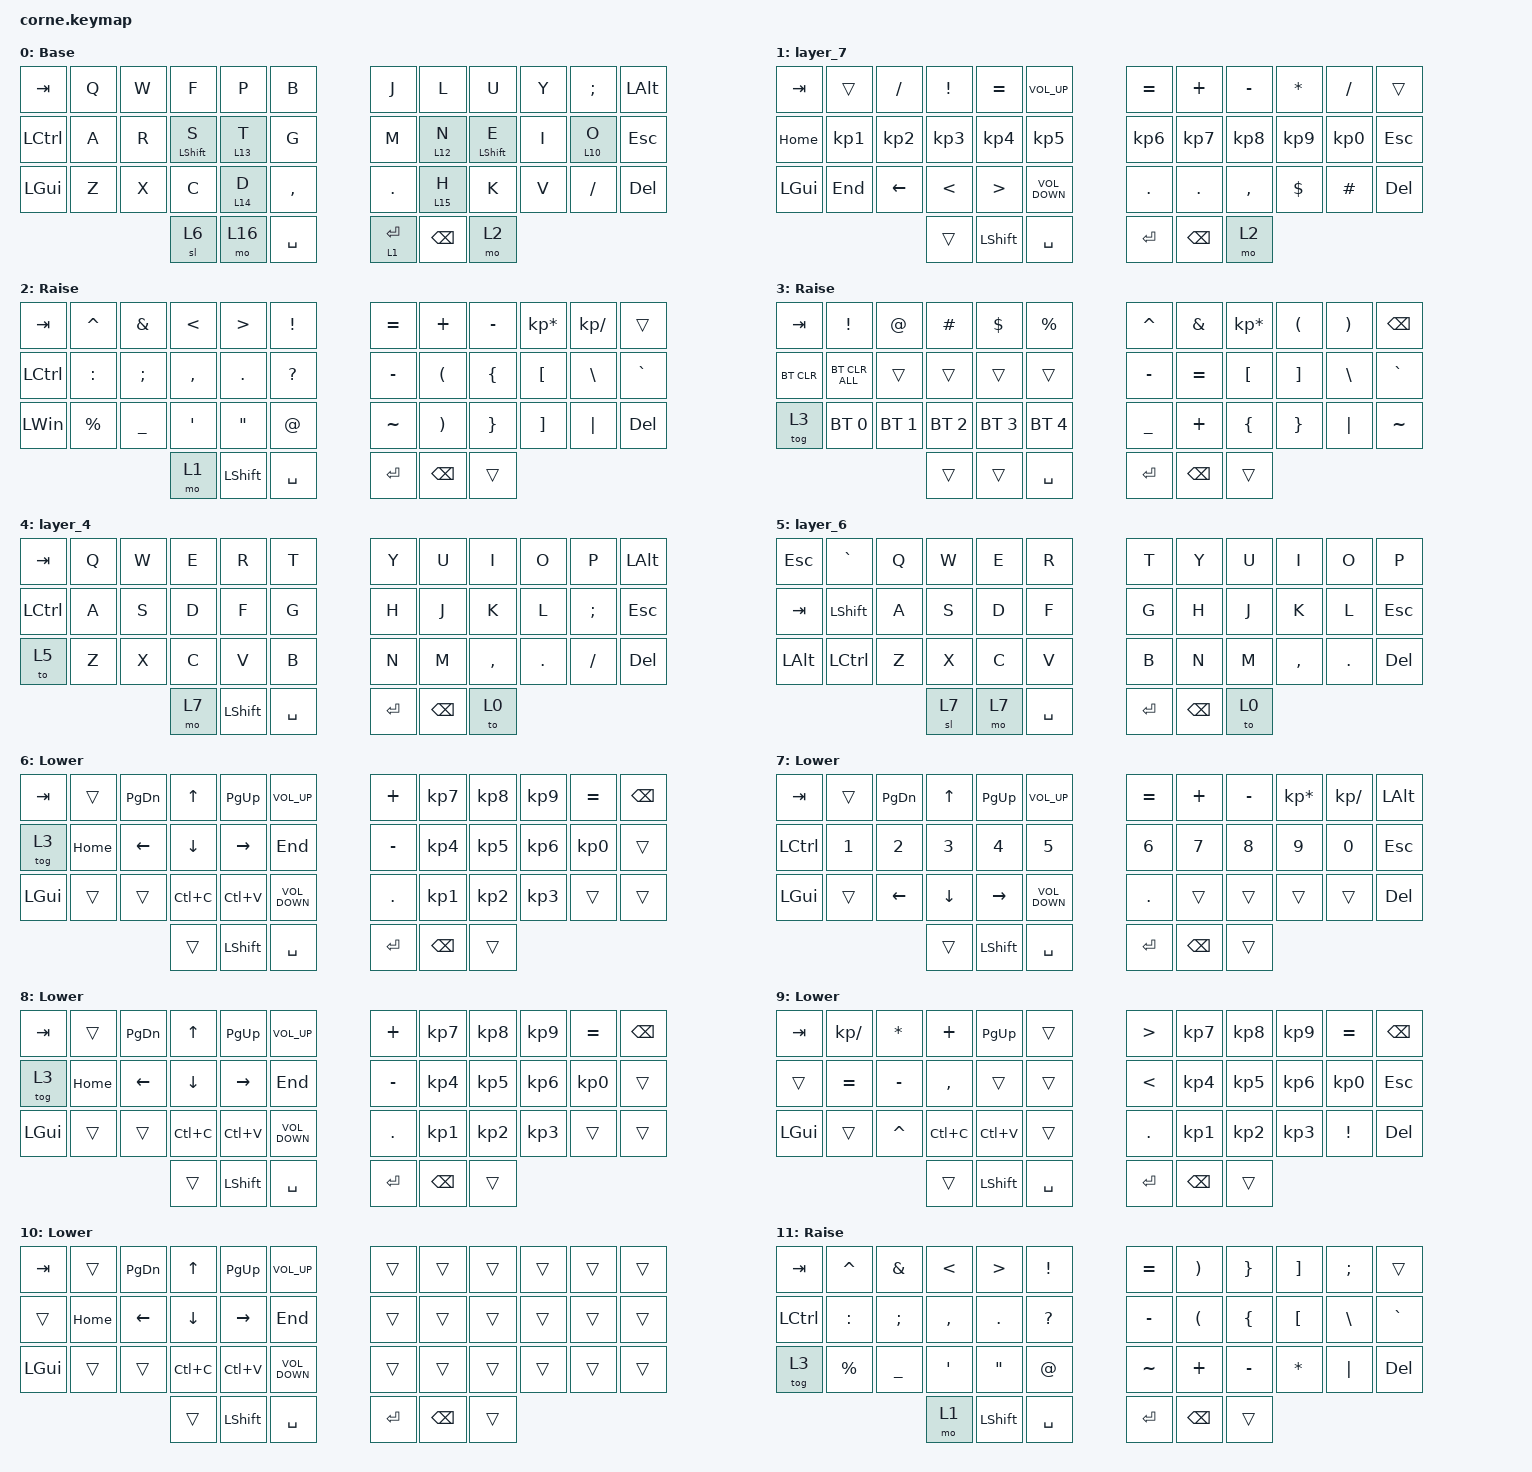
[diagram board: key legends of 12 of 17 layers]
/*
 * Copyright (c) 2020 The ZMK Contributors
 *
 * SPDX-License-Identifier: MIT
 */

#include <behaviors.dtsi>
#include <dt-bindings/zmk/bt.h>
#include <dt-bindings/zmk/keys.h>
#include <dt-bindings/zmk/pointing.h>

/ {
    behaviors {
        HMR: HMR {
            compatible = "zmk,behavior-hold-tap";
            label = "HMR";
            bindings = <&mo>, <&kp>;

            #binding-cells = <2>;
            tapping-term-ms = <200>;
            quick-tap-ms = <175>;
            flavor = "balanced";
            hold-trigger-key-positions = <0 1 2 3 4 5 12 13 14 15 16 17 24 25 26 27 28 29 36 37 38 39 40 41 6 7 8 9 10 11 18 19 20 21 22 23 30 31 32 33 34 35 40 41>;
            hold-trigger-on-release;
        };

        HML: HML {
            compatible = "zmk,behavior-hold-tap";
            label = "HML";
            bindings = <&mo>, <&kp>;

            #binding-cells = <2>;
            tapping-term-ms = <280>;
            quick-tap-ms = <175>;
            flavor = "balanced";
            hold-trigger-on-release;
            hold-trigger-key-positions = <36 37 38 6 7 8 9 10 11 18 19 20 21 22 23 30 31 32 33 34 35 39 40 41>;
            require-prior-idle-ms = <150>;
        };

        HMR2: HMR2 {
            compatible = "zmk,behavior-hold-tap";
            label = "HMR2";
            bindings = <&mo>, <&kp>;

            #binding-cells = <2>;
            tapping-term-ms = <280>;
            quick-tap-ms = <175>;
            flavor = "balanced";
            hold-trigger-on-release;
            hold-trigger-key-positions = <0 1 2 3 4 5 12 13 14 15 16 17 24 25 26 27 28 29 36 37 38 39 40 41>;
            require-prior-idle-ms = <150>;
        };

        HML_Shift: HML_Shift {
            compatible = "zmk,behavior-hold-tap";
            label = "HML_SHIFT";
            bindings = <&kp>, <&kp>;

            #binding-cells = <2>;
            tapping-term-ms = <280>;
            quick-tap-ms = <175>;
            flavor = "balanced";
            hold-trigger-on-release;
            hold-trigger-key-positions = <36 37 38 6 7 8 9 10 11 18 19 20 21 22 23 30 31 32 33 34 35 39 40 41>;
            require-prior-idle-ms = <150>;
        };

        HMR_Shift: HMR_Shift {
            compatible = "zmk,behavior-hold-tap";
            label = "HMR_SHIFT";
            bindings = <&kp>, <&kp>;

            #binding-cells = <2>;
            tapping-term-ms = <280>;
            quick-tap-ms = <175>;
            flavor = "balanced";
            hold-trigger-on-release;
            hold-trigger-key-positions = <0 1 2 3 4 5 12 13 14 15 16 17 24 25 26 27 28 29 36 37 38 39 40 41>;
            require-prior-idle-ms = <150>;
        };
    };

    combos {
        compatible = "zmk,combos";

        wasd {
            bindings = <&to 5>;
            key-positions = <24 12 35 23>;
        };

        home_row_numbers {
            bindings = <&sl 8>;
            key-positions = <36 41>;
        };

        gameObject {
            bindings = <&gameObject>;
            key-positions = <17 22 13>;
        };

        transform {
            bindings = <&transform>;
            key-positions = <16 14 19>;
        };

        this {
            bindings = <&this>;
            key-positions = <16 31 21 15>;
        };

        the {
            bindings = <&the>;
            key-positions = <16 31 20>;
        };

        for {
            bindings = <&for>;
            key-positions = <3 22 14>;
        };

        foreach {
            bindings = <&foreach>;
            key-positions = <3 22 14 20>;
        };

        while {
            bindings = <&while>;
            key-positions = <2 31 21>;
        };

        public {
            bindings = <&public>;
            key-positions = <4 8 7>;
        };

        private {
            bindings = <&private>;
            key-positions = <4 14 21>;
        };

        GameObjectMaj {
            bindings = <&GameObjectMaj>;
            key-positions = <17 22 13 37>;
        };

        TransformMaj {
            bindings = <&TransformMaj>;
            key-positions = <16 14 19 37>;
        };

        BlueTooth {
            bindings = <&tog 3>;
            key-positions = <0 1 13 12>;
        };
    };

    macros {
        gameObject: gameObject {
            compatible = "zmk,behavior-macro";
            #binding-cells = <0>;
            bindings =
                <&macro_tap_time 0>,
                <&kp G &kp A &kp M &kp E &kp LS(O) &kp B &kp J &kp E &kp C &kp T>;

            label = "GAMEOBJECT";
            wait-ms = <0>;
            tap-ms = <0>;
        };

        GameObjectMaj: GameObjectMaj {
            compatible = "zmk,behavior-macro";
            #binding-cells = <0>;
            bindings =
                <&macro_tap_time 0>,
                <&kp LS(G) &kp A &kp M &kp E &kp LS(O) &kp B &kp J &kp E &kp C &kp T>;

            label = "GAMEOBJECTMAJ";
            wait-ms = <0>;
            tap-ms = <0>;
        };

        TransformMaj: TransformMaj {
            compatible = "zmk,behavior-macro";
            #binding-cells = <0>;
            bindings =
                <&macro_tap_time 0>,
                <&kp LS(T) &kp R &kp A &kp N &kp S &kp F &kp O &kp R &kp M>;

            label = "TRANSFORMMAJ";
        };

        public: public {
            compatible = "zmk,behavior-macro";
            #binding-cells = <0>;
            bindings =
                <&macro_tap_time 0>,
                <&kp P &kp U &kp B &kp L &kp I &kp C>;

            label = "PUBLIC";
        };

        private: private {
            compatible = "zmk,behavior-macro";
            #binding-cells = <0>;
            bindings =
                <&macro_tap_time 0>,
                <&kp P &kp R &kp I &kp V &kp A &kp T &kp E>;

            label = "PRIVATE";
        };

        the: the {
            compatible = "zmk,behavior-macro";
            #binding-cells = <0>;
            bindings = <&macro_tap_time 0>, <&kp T &kp H &kp E>;

            label = "THE";
        };

        this: this {
            compatible = "zmk,behavior-macro";
            #binding-cells = <0>;
            bindings = <&macro_tap_time 0>, <&kp T &kp H &kp I &kp S>;

            label = "THIS";
        };

        for: for {
            compatible = "zmk,behavior-macro";
            #binding-cells = <0>;
            bindings = <&macro_tap_time 0>, <&kp F &kp O &kp R>;

            label = "FOR";
        };

        foreach: foreach {
            compatible = "zmk,behavior-macro";
            #binding-cells = <0>;
            bindings =
                <&macro_tap_time 0>,
                <&kp F &kp O &kp R &kp E &kp A &kp C &kp H>;

            label = "FOREACH";
        };

        while: while {
            compatible = "zmk,behavior-macro";
            #binding-cells = <0>;
            bindings = <&macro_tap_time 0>, <&kp W &kp H &kp I &kp L &kp E>;

            label = "WHILE";
        };

        transform: transform {
            compatible = "zmk,behavior-macro";
            #binding-cells = <0>;
            bindings =
                <&macro_tap_time 0>,
                <&kp T &kp R &kp A &kp N &kp S &kp F &kp O &kp R &kp M>;

            label = "TRANSFORM";
            wait-ms = <0>;
            tap-ms = <0>;
        };

        even: even {
            compatible = "zmk,behavior-macro";
            #binding-cells = <0>;
            bindings = <&macro_tap_time 0>, <&kp E &kp V &kp E &kp N &kp SPACE>;

            label = "EVEN";
            wait-ms = <0>;
            tap-ms = <0>;
        };

        made: made {
            compatible = "zmk,behavior-macro";
            #binding-cells = <0>;
            bindings = <&macro_tap_time 0>, <&kp M &kp A &kp D &kp E &kp SPACE>;

            label = "MADE";
            wait-ms = <0>;
            tap-ms = <0>;
        };

        then: then {
            compatible = "zmk,behavior-macro";
            #binding-cells = <0>;
            bindings = <&macro_tap_time 0>, <&kp T &kp H &kp E &kp N &kp SPACE>;

            label = "THEN";
            wait-ms = <0>;
            tap-ms = <0>;
        };

        city: city {
            compatible = "zmk,behavior-macro";
            #binding-cells = <0>;
            bindings = <&macro_tap_time 0>;
            label = "CITY";
            wait-ms = <0>;
            tap-ms = <0>;
        };
    };

    keymap {
        compatible = "zmk,keymap";

        default_layer {
            // -----------------------------------------------------------------------------------------
            // |  TAB |  Q  |  W  |  E  |  R  |  T  |   |  Y  |  U   |  I  |  O  |  P  | BKSP |
            // | CTRL |  A  |  S  |  D  |  F  |  G  |   |  H  |  J   |  K  |  L  |  ;  |  '   |
            // | SHFT |  Z  |  X  |  C  |  V  |  B  |   |  N  |  M   |  ,  |  .  |  /  | ESC  |
            //                    | GUI | LWR | SPC |   | ENT | RSE  | ALT |

            display-name = "Base";
            bindings = <
&kp TAB       &kp Q  &kp W  &kp F                &kp P      &kp B        &kp J          &kp L       &kp U                    &kp Y  &kp SEMICOLON  &kp LEFT_ALT
&kp LCTRL     &kp A  &kp R  &HML_Shift LSHIFT S  &HML 13 T  &kp G        &kp M          &HMR2 12 N  &HMR_Shift LEFT_SHIFT E  &kp I  &HMR2 10 O     &kp ESCAPE
&kp LEFT_GUI  &kp Z  &kp X  &kp C                &HML 14 D  &kp COMMA    &kp DOT        &HMR2 15 H  &kp K                    &kp V  &kp FSLH       &kp DELETE
                            &sl 6                &mo 16     &kp SPACE    &HMR 1 RETURN  &kp BSPC    &mo 2
            >;
        };

        layer_7 {
            bindings = <
&kp TAB   &trans           &kp SLASH  &kp EXCLAMATION  &kp EQUAL         &kp C_VOLUME_UP      &kp EQUAL        &kp PLUS         &kp MINUS        &kp STAR         &kp FSLH         &trans
&kp HOME  &kp KP_NUMBER_1  &kp KP_N2  &kp KP_NUMBER_3  &kp KP_NUMBER_4   &kp KP_NUMBER_5      &kp KP_NUMBER_6  &kp KP_NUMBER_7  &kp KP_NUMBER_8  &kp KP_NUMBER_9  &kp KP_NUMBER_0  &kp ESC
&kp LGUI  &kp END          &kp LEFT   &kp LESS_THAN    &kp GREATER_THAN  &kp C_VOLUME_DOWN    &kp DOT          &kp DOT          &kp COMMA        &kp DOLLAR       &kp HASH         &kp DEL
                                      &trans           &kp LEFT_SHIFT    &kp SPACE            &kp RET          &kp BSPC         &mo 2
            >;
        };

        raise_layer {
            // -----------------------------------------------------------------------------------------
            // |  TAB |  !  |  @  |  #  |  $  |  %  |   |  ^  |  &  |  *  |  (  |  )  | BKSP |
            // | CTRL |     |     |     |     |     |   |  -  |  =  |  [  |  ]  |  \  |  `   |
            // | SHFT |     |     |     |     |     |   |  _  |  +  |  {  |  }  | "|" |  ~   |
            //                    | GUI |     | SPC |   | ENT |     | ALT |

            display-name = "Raise";
            bindings = <
&kp TAB       &kp CARET    &kp AMPERSAND  &kp LESS_THAN  &kp GREATER_THAN   &kp EXCL        &kp EQUAL  &kp PLUS               &kp MINUS        &kp KP_MULTIPLY    &kp KP_DIVIDE  &trans
&kp LCTRL     &kp COLON    &kp SEMI       &kp COMMA      &kp DOT            &kp QUESTION    &kp MINUS  &kp LEFT_PARENTHESIS   &kp LEFT_BRACE   &kp LEFT_BRACKET   &kp BSLH       &kp GRAVE
&kp LEFT_WIN  &kp PERCENT  &kp UNDER      &kp SQT        &kp DOUBLE_QUOTES  &kp AT          &kp TILDE  &kp RIGHT_PARENTHESIS  &kp RIGHT_BRACE  &kp RIGHT_BRACKET  &kp PIPE       &kp DEL
                                          &mo 1          &kp LEFT_SHIFT     &kp SPACE       &kp RET    &kp BACKSPACE          &trans
            >;
        };

        layer_3 {
            display-name = "Raise";
            bindings = <
&kp TAB     &kp EXCL        &kp AT        &kp HASH      &kp DLLR      &kp PRCNT       &kp CARET  &kp AMPS       &kp KP_MULTIPLY  &kp LPAR  &kp RPAR  &kp BSPC
&bt BT_CLR  &bt BT_CLR_ALL  &trans        &trans        &trans        &trans          &kp MINUS  &kp EQUAL      &kp LBKT         &kp RBKT  &kp BSLH  &kp GRAVE
&tog 3      &bt BT_SEL 0    &bt BT_SEL 1  &bt BT_SEL 2  &bt BT_SEL 3  &bt BT_SEL 4    &kp UNDER  &kp PLUS       &kp LBRC         &kp RBRC  &kp PIPE  &kp TILDE
                                          &trans        &trans        &kp SPACE       &kp RET    &kp BACKSPACE  &trans
            >;
        };

        layer_4 {
            bindings = <
&kp TAB    &kp Q  &kp W  &kp E  &kp R      &kp T        &kp Y      &kp U     &kp I      &kp O    &kp P     &kp LALT
&kp LCTRL  &kp A  &kp S  &kp D  &kp F      &kp G        &kp H      &kp J     &kp K      &kp L    &kp SEMI  &kp ESC
&to 5      &kp Z  &kp X  &kp C  &kp V      &kp B        &kp N      &kp M     &kp COMMA  &kp DOT  &kp FSLH  &kp DEL
                         &mo 7  &kp LSHFT  &kp SPACE    &kp ENTER  &kp BSPC  &to 0
            >;
        };

        layer_6 {
            bindings = <
&kp ESC   &kp GRAVE         &kp Q  &kp W  &kp E  &kp R        &kp T      &kp Y     &kp U  &kp I      &kp O    &kp P
&kp TAB   &kp LSHFT         &kp A  &kp S  &kp D  &kp F        &kp G      &kp H     &kp J  &kp K      &kp L    &kp ESC
&kp LALT  &kp LEFT_CONTROL  &kp Z  &kp X  &kp C  &kp V        &kp B      &kp N     &kp M  &kp COMMA  &kp DOT  &kp DEL
                                   &sl 7  &mo 7  &kp SPACE    &kp ENTER  &kp BSPC  &to 0
            >;
        };

        lower_layer {
            // -----------------------------------------------------------------------------------------
            // |  TAB |  1  |  2  |  3  |  4  |  5  |   |  6  |  7  |  8  |  9  |  0  | BKSP |
            // | BTCLR| BT1 | BT2 | BT3 | BT4 | BT5 |   | LFT | DWN |  UP | RGT |     |      |
            // | SHFT |     |     |     |     |     |   |     |     |     |     |     |      |
            //                    | GUI |     | SPC |   | ENT |     | ALT |

            display-name = "Lower";
            bindings = <
&kp TAB       &trans    &kp PAGE_DOWN  &kp UP     &kp PAGE_UP     &kp C_VOLUME_UP      &kp PLUS   &kp KP_NUMBER_7  &kp KP_NUMBER_8  &kp KP_NUMBER_9  &kp EQUAL        &kp BSPC
&tog 3        &kp HOME  &kp LEFT       &kp DOWN   &kp RIGHT       &kp END              &kp MINUS  &kp KP_NUMBER_4  &kp KP_NUMBER_5  &kp KP_NUMBER_6  &kp KP_NUMBER_0  &trans
&kp LEFT_GUI  &trans    &trans         &kp LC(C)  &kp LC(V)       &kp C_VOLUME_DOWN    &kp DOT    &kp KP_NUMBER_1  &kp KP_NUMBER_2  &kp KP_NUMBER_3  &trans           &trans
                                       &trans     &kp LEFT_SHIFT  &kp SPACE            &kp RET    &kp BSPC         &trans
            >;
        };

        layer_5 {
            display-name = "Lower";
            bindings = <
&kp TAB    &trans  &kp PAGE_DOWN  &kp UP    &kp PAGE_UP     &kp C_VOLUME_UP      &kp EQUAL  &kp PLUS  &kp MINUS  &kp KP_MULTIPLY  &kp KP_DIVIDE  &kp LALT
&kp LCTRL  &kp N1  &kp N2         &kp N3    &kp N4          &kp N5               &kp N6     &kp N7    &kp N8     &kp N9           &kp N0         &kp ESC
&kp LGUI   &trans  &kp LEFT       &kp DOWN  &kp RIGHT       &kp C_VOLUME_DOWN    &kp DOT    &trans    &trans     &trans           &trans         &kp DEL
                                  &trans    &kp LEFT_SHIFT  &kp SPACE            &kp RET    &kp BSPC  &trans
            >;
        };

        layer_9 {
            display-name = "Lower";
            bindings = <
&kp TAB       &trans    &kp PAGE_DOWN  &kp UP     &kp PAGE_UP     &kp C_VOLUME_UP      &kp PLUS   &kp KP_NUMBER_7  &kp KP_NUMBER_8  &kp KP_NUMBER_9  &kp EQUAL        &kp BSPC
&tog 3        &kp HOME  &kp LEFT       &kp DOWN   &kp RIGHT       &kp END              &kp MINUS  &kp KP_NUMBER_4  &kp KP_NUMBER_5  &kp KP_NUMBER_6  &kp KP_NUMBER_0  &trans
&kp LEFT_GUI  &trans    &trans         &kp LC(C)  &kp LC(V)       &kp C_VOLUME_DOWN    &kp DOT    &kp KP_NUMBER_1  &kp KP_NUMBER_2  &kp KP_NUMBER_3  &trans           &trans
                                       &trans     &kp LEFT_SHIFT  &kp SPACE            &kp RET    &kp BSPC         &trans
            >;
        };

        HomeRowNUMPad {
            display-name = "Lower";
            bindings = <
&kp TAB       &kp KP_DIVIDE  &kp ASTERISK  &kp PLUS   &kp PAGE_UP     &trans       &kp GREATER_THAN  &kp KP_NUMBER_7  &kp KP_NUMBER_8  &kp KP_NUMBER_9  &kp EQUAL        &kp BSPC
&trans        &kp EQUAL      &kp MINUS     &kp COMMA  &trans          &trans       &kp LESS_THAN     &kp KP_NUMBER_4  &kp KP_NUMBER_5  &kp KP_NUMBER_6  &kp KP_NUMBER_0  &kp ESC
&kp LEFT_GUI  &trans         &kp CARET     &kp LC(C)  &kp LC(V)       &trans       &kp DOT           &kp KP_NUMBER_1  &kp KP_NUMBER_2  &kp KP_NUMBER_3  &kp EXCLAMATION  &kp DELETE
                                           &trans     &kp LEFT_SHIFT  &kp SPACE    &kp RET           &kp BSPC         &trans
            >;
        };

        HomeRowArrows {
            display-name = "Lower";
            bindings = <
&kp TAB       &trans    &kp PAGE_DOWN  &kp UP     &kp PAGE_UP     &kp C_VOLUME_UP      &trans   &trans    &trans  &trans  &trans  &trans
&trans        &kp HOME  &kp LEFT       &kp DOWN   &kp RIGHT       &kp END              &trans   &trans    &trans  &trans  &trans  &trans
&kp LEFT_GUI  &trans    &trans         &kp LC(C)  &kp LC(V)       &kp C_VOLUME_DOWN    &trans   &trans    &trans  &trans  &trans  &trans
                                       &trans     &kp LEFT_SHIFT  &kp SPACE            &kp RET  &kp BSPC  &trans
            >;
        };

        HomeRowLayerParentheses {
            display-name = "Raise";
            bindings = <
&kp TAB    &kp CARET    &kp AMPERSAND  &kp LESS_THAN  &kp GREATER_THAN   &kp EXCL        &kp EQUAL  &kp RIGHT_PARENTHESIS  &kp RIGHT_BRACE  &kp RBKT          &kp SEMI  &trans
&kp LCTRL  &kp COLON    &kp SEMI       &kp COMMA      &kp DOT            &kp QUESTION    &kp MINUS  &kp LEFT_PARENTHESIS   &kp LEFT_BRACE   &kp LEFT_BRACKET  &kp BSLH  &kp GRAVE
&tog 3     &kp PERCENT  &kp UNDER      &kp SQT        &kp DOUBLE_QUOTES  &kp AT          &kp TILDE  &kp PLUS               &kp MINUS        &kp STAR          &kp PIPE  &kp DELETE
                                       &mo 1          &kp LEFT_SHIFT     &kp SPACE       &kp RET    &kp BACKSPACE          &trans
            >;
        };

        HomeRowParenthesesFingersRight {
            display-name = "Raise";
            bindings = <
&kp TAB    &kp CARET    &kp AMPERSAND  &kp LESS_THAN     &kp GREATER_THAN   &kp EXCL        &trans   &trans         &trans  &trans  &trans  &trans
&kp LCTRL  &kp COLON    &kp SEMI       &kp COMMA         &kp DOT            &kp QUESTION    &trans   &trans         &trans  &trans  &trans  &kp GRAVE
&tog 3     &kp PERCENT  &kp UNDER      &kp SINGLE_QUOTE  &kp DOUBLE_QUOTES  &kp AT          &trans   &trans         &trans  &trans  &trans  &kp DELETE
                                       &mo 1             &kp LEFT_SHIFT     &kp SPACE       &kp RET  &kp BACKSPACE  &trans
            >;
        };

        HomeRowParenthesesFingersLeft {
            display-name = "Raise";
            bindings = <
&kp TAB       &trans  &trans  &trans  &trans          &trans       &kp EQUAL  &kp RIGHT_PARENTHESIS  &kp RIGHT_BRACE  &kp RBKT          &kp SEMI  &trans
&kp LCTRL     &trans  &trans  &trans  &trans          &trans       &kp MINUS  &kp LEFT_PARENTHESIS   &kp LEFT_BRACE   &kp LEFT_BRACKET  &kp BSLH  &kp GRAVE
&kp LEFT_WIN  &trans  &trans  &trans  &trans          &trans       &kp TILDE  &kp PLUS               &kp MINUS        &kp STAR          &kp PIPE  &kp DELETE
                              &mo 1   &kp LEFT_SHIFT  &kp SPACE    &kp RET    &kp BACKSPACE          &trans
            >;
        };

        LeftHandNumHomeRow {
            bindings = <
&kp TAB           &trans  &trans  &trans  &trans          &trans       &kp EQUAL        &kp PLUS              &kp MINUS       &kp STAR                           &kp FSLH              &trans
&kp LEFT_CONTROL  &trans  &trans  &trans  &trans          &trans       &kp KP_NUMBER_6  &HMR2 12 KP_NUMBER_7  &HMR2 15 KP_N8  &HMR_Shift LEFT_SHIFT KP_NUMBER_9  &HMR2 10 KP_NUMBER_0  &kp ESC
&kp LGUI          &trans  &trans  &trans  &trans          &trans       &kp DOT          &HMR2 15 PERIOD       &kp COMMA       &kp DOLLAR                         &kp HASH              &kp DEL
                                  &trans  &kp LEFT_SHIFT  &kp SPACE    &kp RET          &kp BSPC              &mo 2
            >;
        };

        RightHandNumHomeRow {
            bindings = <
&kp TAB           &kp FSLH         &kp STAR                           &kp MINUS      &kp PLUS        &kp EQUAL            &trans   &trans    &trans  &trans  &trans  &trans
&kp LEFT_CONTROL  &kp KP_NUMBER_1  &HML_Shift LEFT_SHIFT KP_NUMBER_2  &HML 14 KP_N3  &HML 13 KP_N4   &kp KP_NUMBER_5      &trans   &trans    &trans  &trans  &trans  &kp ESC
&kp LGUI          &kp END          &trans                             &kp COMMA      &HML 14 PERIOD  &kp C_VOLUME_DOWN    &trans   &trans    &trans  &trans  &trans  &kp DEL
                                                                      &trans         &kp LEFT_SHIFT  &kp SPACE            &kp RET  &kp BSPC  &mo 2
            >;
        };

        layer_16 {
            bindings = <
&trans  &trans  &msc SCRL_UP    &mmv MOVE_UP    &msc SCRL_DOWN   &trans    &trans  &trans  &trans  &trans  &trans  &trans
&trans  &trans  &mmv MOVE_LEFT  &mmv MOVE_DOWN  &mmv MOVE_RIGHT  &trans    &trans  &trans  &trans  &trans  &trans  &trans
&trans  &trans  &mkp MB2        &mkp MB3        &mkp LCLK        &trans    &trans  &trans  &trans  &trans  &trans  &trans
                                &kp SPACE       &trans           &trans    &trans  &trans  &trans
            >;
        };
    };
};
